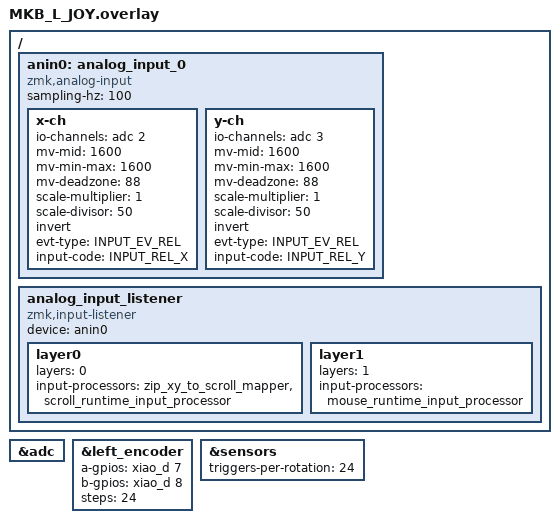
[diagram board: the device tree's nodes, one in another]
#include <zephyr/dt-bindings/input/input-event-codes.h>
#include <input/processors.dtsi>
#include <dt-bindings/zmk/input_transform.h>
#include <dt-bindings/zmk/keys.h>

&adc {
    status = "okay";
};

&left_encoder {
    a-gpios = <&xiao_d 7 (GPIO_ACTIVE_HIGH | GPIO_PULL_UP)>;
    b-gpios = <&xiao_d 8 (GPIO_ACTIVE_HIGH | GPIO_PULL_UP)>;
    /* 修正：1クリックで1反応にするため一般的な24ステップに設定 */
    steps = <24>;
    status = "okay";
};

&sensors {
    /* 修正：stepsと同じ値にすることで1ノッチ=1入力になります */
    triggers-per-rotation = <24>;
};

/ {
    anin0: analog_input_0 {
        compatible = "zmk,analog-input";
        sampling-hz = <100>;
        x-ch {
            io-channels = <&adc 2>;
            mv-mid = <1600>;
            mv-min-max = <1600>;
            mv-deadzone = <88>;
            scale-multiplier = <1>;
            scale-divisor = <50>; 
            invert;
            evt-type = <INPUT_EV_REL>;
            input-code = <INPUT_REL_X>;
        };
        y-ch {
            io-channels = <&adc 3>;
            mv-mid = <1600>;
            mv-min-max = <1600>;
            mv-deadzone = <88>;
            scale-multiplier = <1>;
            scale-divisor = <50>; 
            invert;
            evt-type = <INPUT_EV_REL>;
            input-code = <INPUT_REL_Y>;
        };
    };

    analog_input_listener {
        status = "okay";
        compatible = "zmk,input-listener";
        device = <&anin0>;
        
        layer0 {
            layers = <0>;
            input-processors = <&zip_xy_to_scroll_mapper>, <&scroll_runtime_input_processor>;
        };

        layer1 {
            layers = <1>;
            input-processors = <&mouse_runtime_input_processor>;
        };
    };
};
